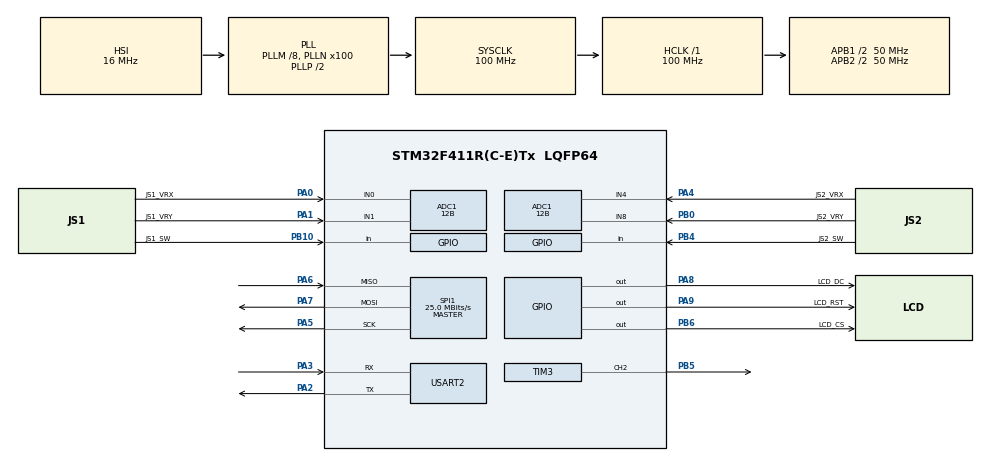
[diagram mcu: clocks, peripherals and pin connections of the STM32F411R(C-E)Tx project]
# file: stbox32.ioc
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ADC1.Channel-0\#ChannelRegularConversion=ADC_CHANNEL_0
ADC1.Channel-6\#ChannelRegularConversion=ADC_CHANNEL_1
ADC1.Channel-7\#ChannelRegularConversion=ADC_CHANNEL_4
ADC1.Channel-8\#ChannelRegularConversion=ADC_CHANNEL_8
ADC1.ContinuousConvMode=ENABLE
ADC1.EOCSelection=ADC_EOC_SINGLE_CONV
ADC1.NbrOfConversion=4
ADC1.NbrOfConversionFlag=1
ADC1.Rank-0\#ChannelRegularConversion=1
ADC1.Rank-6\#ChannelRegularConversion=2
ADC1.Rank-7\#ChannelRegularConversion=3
ADC1.Rank-8\#ChannelRegularConversion=4
ADC1.Resolution=ADC_RESOLUTION_12B
ADC1.SamplingTime-0\#ChannelRegularConversion=ADC_SAMPLETIME_15CYCLES
ADC1.SamplingTime-6\#ChannelRegularConversion=ADC_SAMPLETIME_15CYCLES
ADC1.SamplingTime-7\#ChannelRegularConversion=ADC_SAMPLETIME_15CYCLES
ADC1.SamplingTime-8\#ChannelRegularConversion=ADC_SAMPLETIME_15CYCLES
ADC1.ScanConvMode=ENABLE
ADC1.master=1
Dma.ADC1.0.Direction=DMA_PERIPH_TO_MEMORY
Dma.ADC1.0.FIFOMode=DMA_FIFOMODE_DISABLE
Dma.ADC1.0.Instance=DMA2_Stream0
Dma.ADC1.0.MemDataAlignment=DMA_MDATAALIGN_WORD
Dma.ADC1.0.MemInc=DMA_MINC_ENABLE
Dma.ADC1.0.Mode=DMA_CIRCULAR
Dma.ADC1.0.PeriphDataAlignment=DMA_PDATAALIGN_WORD
Dma.ADC1.0.PeriphInc=DMA_PINC_DISABLE
Dma.ADC1.0.Priority=DMA_PRIORITY_LOW
Dma.Request0=ADC1
Mcu.Family=STM32F4
Mcu.Name=STM32F411R(C-E)Tx
Mcu.Package=LQFP64
NVIC.ADC_IRQn=true\:0\:0\:false\:false\:true\:true\:true\:true
NVIC.DMA2_Stream0_IRQn=true\:0\:0\:false\:false\:true\:false\:true\:true
NVIC.PriorityGroup=NVIC_PRIORITYGROUP_0
NVIC.SPI1_IRQn=true\:0\:0\:false\:false\:true\:true\:true\:true
NVIC.USART2_IRQn=true\:0\:0\:false\:false\:true\:true\:true\:true
PA0-WKUP.GPIO_Label=JS1_VRX
PA0-WKUP.Signal=ADCx_IN0
PA1.GPIO_Label=JS1_VRY
PA1.Signal=ADCx_IN1
PA2.Mode=Asynchronous
PA2.Signal=USART2_TX
PA3.GPIO_PuPd=GPIO_NOPULL
PA3.Mode=Asynchronous
PA3.Signal=USART2_RX
PA4.GPIO_Label=JS2_VRX
PA4.Signal=ADCx_IN4
PA5.Mode=Full_Duplex_Master
PA5.Signal=SPI1_SCK
PA6.GPIO_PuPd=GPIO_NOPULL
PA6.Mode=Full_Duplex_Master
PA6.Signal=SPI1_MISO
PA7.Mode=Full_Duplex_Master
PA7.Signal=SPI1_MOSI
PA8.GPIO_Label=LCD_DC
PA8.GPIO_PuPd=GPIO_NOPULL
PA8.GPIO_Speed=GPIO_SPEED_FREQ_MEDIUM
PA8.PinState=GPIO_PIN_SET
PA8.Signal=GPIO_Output
PA9.GPIO_Label=LCD_RST
PA9.GPIO_PuPd=GPIO_NOPULL
PA9.GPIO_Speed=GPIO_SPEED_FREQ_VERY_HIGH
PA9.PinState=GPIO_PIN_SET
PA9.Signal=GPIO_Output
PB0.GPIO_Label=JS2_VRY
PB0.Signal=ADCx_IN8
PB10.GPIO_Label=JS1_SW
PB10.GPIO_PuPd=GPIO_PULLUP
PB10.Signal=GPIO_Input
PB4.GPIO_Label=JS2_SW
PB4.GPIO_PuPd=GPIO_PULLUP
PB4.Signal=GPIO_Input
PB5.Signal=S_TIM3_CH2
PB6.GPIO_Label=LCD_CS
PB6.GPIO_PuPd=GPIO_NOPULL
PB6.GPIO_Speed=GPIO_SPEED_FREQ_MEDIUM
PB6.PinState=GPIO_PIN_SET
PB6.Signal=GPIO_Output
PH0\ -\ OSC_IN.Mode=HSE-External-Oscillator
PH0\ -\ OSC_IN.Signal=RCC_OSC_IN
PH1\ -\ OSC_OUT.Mode=HSE-External-Oscillator
PH1\ -\ OSC_OUT.Signal=RCC_OSC_OUT
ProjectManager.HeapSize=0x200
ProjectManager.StackSize=0x400
ProjectManager.TargetToolchain=STM32CubeIDE
RCC.48MHZClocksFreq_Value=50000000
RCC.AHBFreq_Value=100000000
RCC.APB1CLKDivider=RCC_HCLK_DIV2
RCC.APB1Freq_Value=50000000
RCC.APB1TimFreq_Value=100000000
RCC.APB2CLKDivider=RCC_HCLK_DIV2
RCC.APB2Freq_Value=50000000
RCC.APB2TimFreq_Value=100000000
RCC.CortexFreq_Value=100000000
RCC.FLatency-AdvancedSettings=FLASH_LATENCY_3
RCC.HCLKFreq_Value=100000000
RCC.HSE_VALUE=8000000
RCC.HSI_VALUE=16000000
RCC.LSE_VALUE=32768
RCC.PLLM=8
RCC.PLLN=100
RCC.SYSCLKFreq_VALUE=100000000
RCC.SYSCLKSource=RCC_SYSCLKSOURCE_PLLCLK
RCC.VCOOutputFreq_Value=200000000
RTC.Hours=3
RTC.Minutes=30
RTC.Seconds=30
SH.ADCx_IN0.0=ADC1_IN0,IN0
SH.ADCx_IN1.0=ADC1_IN1,IN1
SH.ADCx_IN4.0=ADC1_IN4,IN4
SH.ADCx_IN8.0=ADC1_IN8,IN8
SH.S_TIM3_CH2.0=TIM3_CH2,PWM Generation2 CH2
SPI1.CalculateBaudRate=25.0 MBits/s
SPI1.Direction=SPI_DIRECTION_2LINES
SPI1.Mode=SPI_MODE_MASTER
SPI1.VirtualType=VM_MASTER
TIM3.Channel-PWM\ Generation2\ CH2=TIM_CHANNEL_2
TIM3.Period=999
TIM3.Prescaler=83
USART2.VirtualMode=VM_ASYNC
VP_RTC_VS_RTC_Activate.Mode=RTC_Enabled
VP_RTC_VS_RTC_Calendar.Mode=RTC_Calendar
VP_TIM3_VS_ClockSourceINT.Mode=Internal
board=NUCLEO-F411RE

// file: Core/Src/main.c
/* USER CODE BEGIN Header */
/**
  ******************************************************************************
  * @file           : main.c
  * @brief          : Main program body
  ******************************************************************************
  * @attention
  *
  * Copyright (c) 2025 STMicroelectronics.
  * All rights reserved.
  *
  * This software is licensed under terms that can be found in the LICENSE file
  * in the root directory of this software component.
  * If no LICENSE file comes with this software, it is provided AS-IS.
  *
  ******************************************************************************
  */
/* USER CODE END Header */
#include "main.h"

/* USER CODE BEGIN Includes */
#include "main_menu.h"
/* USER CODE END Includes */

ADC_HandleTypeDef hadc1;
DMA_HandleTypeDef hdma_adc1;

RTC_HandleTypeDef hrtc;

SPI_HandleTypeDef hspi1;

TIM_HandleTypeDef htim3;

UART_HandleTypeDef huart2;

void SystemClock_Config(void);
static void MX_GPIO_Init(void);
static void MX_DMA_Init(void);
static void MX_RTC_Init(void);
static void MX_SPI1_Init(void);
static void MX_USART2_UART_Init(void);
static void MX_ADC1_Init(void);
static void MX_TIM3_Init(void);

int main(void)
{

  /* MCU Configuration--------------------------------------------------------*/

  /* Reset of all peripherals, Initializes the Flash interface and the Systick. */
  HAL_Init();

  /* Configure the system clock */
  SystemClock_Config();

  /* Initialize all configured peripherals */
  MX_GPIO_Init();
  MX_DMA_Init();
  MX_RTC_Init();
  MX_SPI1_Init();
  MX_USART2_UART_Init();  MX_ADC1_Init();
  MX_TIM3_Init();
  /* USER CODE BEGIN 2 */
  HAL_TIM_PWM_Start(&htim3, TIM_CHANNEL_2);
  Joystick_Init();  // Initialize joysticks after ADC
  lcd_init();
  srand(HAL_GetTick());
  HAL_ADC_Start(&hadc1);

  lcd_clear_screen(BLACK);  /* USER CODE END 2 */  /* Infinite loop */
  /* USER CODE BEGIN WHILE */

  // Start the main menu system
  main_menu_run();

  while (1)
  {
    /* USER CODE END WHILE */

  }
}

void SystemClock_Config(void)
{
  RCC_OscInitTypeDef RCC_OscInitStruct = {0};
  RCC_ClkInitTypeDef RCC_ClkInitStruct = {0};

  /** Configure the main internal regulator output voltage
  */
  __HAL_RCC_PWR_CLK_ENABLE();
  __HAL_PWR_VOLTAGESCALING_CONFIG(PWR_REGULATOR_VOLTAGE_SCALE1);

  /** Initializes the RCC Oscillators according to the specified parameters
  * in the RCC_OscInitTypeDef structure.
  */
  RCC_OscInitStruct.OscillatorType = RCC_OSCILLATORTYPE_HSI|RCC_OSCILLATORTYPE_LSI;
  RCC_OscInitStruct.HSIState = RCC_HSI_ON;
  RCC_OscInitStruct.HSICalibrationValue = RCC_HSICALIBRATION_DEFAULT;
  RCC_OscInitStruct.LSIState = RCC_LSI_ON;
  RCC_OscInitStruct.PLL.PLLState = RCC_PLL_ON;
  RCC_OscInitStruct.PLL.PLLSource = RCC_PLLSOURCE_HSI;
  RCC_OscInitStruct.PLL.PLLM = 8;
  RCC_OscInitStruct.PLL.PLLN = 100;
  RCC_OscInitStruct.PLL.PLLP = RCC_PLLP_DIV2;
  RCC_OscInitStruct.PLL.PLLQ = 4;
  if (HAL_RCC_OscConfig(&RCC_OscInitStruct) != HAL_OK)
  {
    Error_Handler();
  }

  /** Initializes the CPU, AHB and APB buses clocks
  */
  RCC_ClkInitStruct.ClockType = RCC_CLOCKTYPE_HCLK|RCC_CLOCKTYPE_SYSCLK
                              |RCC_CLOCKTYPE_PCLK1|RCC_CLOCKTYPE_PCLK2;
  RCC_ClkInitStruct.SYSCLKSource = RCC_SYSCLKSOURCE_PLLCLK;
  RCC_ClkInitStruct.AHBCLKDivider = RCC_SYSCLK_DIV1;
  RCC_ClkInitStruct.APB1CLKDivider = RCC_HCLK_DIV2;
  RCC_ClkInitStruct.APB2CLKDivider = RCC_HCLK_DIV2;

  if (HAL_RCC_ClockConfig(&RCC_ClkInitStruct, FLASH_LATENCY_3) != HAL_OK)
  {
    Error_Handler();
  }
}

static void MX_ADC1_Init(void)
{

  ADC_ChannelConfTypeDef sConfig = {0};

  /** Configure the global features of the ADC (Clock, Resolution, Data Alignment and number of conversion)
  */
  hadc1.Instance = ADC1;
  hadc1.Init.ClockPrescaler = ADC_CLOCK_SYNC_PCLK_DIV2;
  hadc1.Init.Resolution = ADC_RESOLUTION_12B;
  hadc1.Init.ScanConvMode = ENABLE;
  hadc1.Init.ContinuousConvMode = ENABLE;
  hadc1.Init.DiscontinuousConvMode = DISABLE;
  hadc1.Init.ExternalTrigConvEdge = ADC_EXTERNALTRIGCONVEDGE_NONE;
  hadc1.Init.ExternalTrigConv = ADC_SOFTWARE_START;  hadc1.Init.DataAlign = ADC_DATAALIGN_RIGHT;
  hadc1.Init.NbrOfConversion = 4;  // Changed from 2 to 4 channels
  hadc1.Init.DMAContinuousRequests = DISABLE;
  hadc1.Init.EOCSelection = ADC_EOC_SINGLE_CONV;
  if (HAL_ADC_Init(&hadc1) != HAL_OK)
  {
    Error_Handler();
  }

  /** Configure for the selected ADC regular channel its corresponding rank in the sequencer and its sample time.
  */
  sConfig.Channel = ADC_CHANNEL_0;
  sConfig.Rank = 1;
  sConfig.SamplingTime = ADC_SAMPLETIME_15CYCLES;
  if (HAL_ADC_ConfigChannel(&hadc1, &sConfig) != HAL_OK)
  {
    Error_Handler();
  }
  /** Configure for the selected ADC regular channel its corresponding rank in the sequencer and its sample time.
  */
  sConfig.Channel = ADC_CHANNEL_1;
  sConfig.Rank = 2;
  if (HAL_ADC_ConfigChannel(&hadc1, &sConfig) != HAL_OK)
  {
    Error_Handler();
  }

  /** Configure for the selected ADC regular channel its corresponding rank in the sequencer and its sample time.
  */
  sConfig.Channel = ADC_CHANNEL_4;
  sConfig.Rank = 3;
  sConfig.SamplingTime = ADC_SAMPLETIME_15CYCLES;
  if (HAL_ADC_ConfigChannel(&hadc1, &sConfig) != HAL_OK)
  {
    Error_Handler();
  }

  /** Configure for the selected ADC regular channel its corresponding rank in the sequencer and its sample time.
  */
  sConfig.Channel = ADC_CHANNEL_8;
  sConfig.Rank = 4;
  sConfig.SamplingTime = ADC_SAMPLETIME_15CYCLES;
  if (HAL_ADC_ConfigChannel(&hadc1, &sConfig) != HAL_OK)
  {
    Error_Handler();
  }

}

static void MX_RTC_Init(void)
{

  RTC_TimeTypeDef sTime = {0};
  RTC_DateTypeDef sDate = {0};

  /** Initialize RTC Only
  */
  hrtc.Instance = RTC;
  hrtc.Init.HourFormat = RTC_HOURFORMAT_24;
  hrtc.Init.AsynchPrediv = 127;
  hrtc.Init.SynchPrediv = 255;
  hrtc.Init.OutPut = RTC_OUTPUT_DISABLE;
  hrtc.Init.OutPutPolarity = RTC_OUTPUT_POLARITY_HIGH;
  hrtc.Init.OutPutType = RTC_OUTPUT_TYPE_OPENDRAIN;
  if (HAL_RTC_Init(&hrtc) != HAL_OK)
  {
    Error_Handler();
  }

  /** Initialize RTC and set the Time and Date
  */
  sTime.Hours = 0x3;
  sTime.Minutes = 0x30;
  sTime.Seconds = 0x30;
  sTime.DayLightSaving = RTC_DAYLIGHTSAVING_NONE;
  sTime.StoreOperation = RTC_STOREOPERATION_RESET;
  if (HAL_RTC_SetTime(&hrtc, &sTime, RTC_FORMAT_BCD) != HAL_OK)
  {
    Error_Handler();
  }
  sDate.WeekDay = RTC_WEEKDAY_MONDAY;
  sDate.Month = RTC_MONTH_JANUARY;
  sDate.Date = 0x1;
  sDate.Year = 0x0;

  if (HAL_RTC_SetDate(&hrtc, &sDate, RTC_FORMAT_BCD) != HAL_OK)
  {
    Error_Handler();
  }

}

static void MX_SPI1_Init(void)
{

  /* SPI1 parameter configuration*/
  hspi1.Instance = SPI1;
  hspi1.Init.Mode = SPI_MODE_MASTER;
  hspi1.Init.Direction = SPI_DIRECTION_2LINES;
  hspi1.Init.DataSize = SPI_DATASIZE_8BIT;
  hspi1.Init.CLKPolarity = SPI_POLARITY_LOW;
  hspi1.Init.CLKPhase = SPI_PHASE_1EDGE;
  hspi1.Init.NSS = SPI_NSS_SOFT;
  hspi1.Init.BaudRatePrescaler = SPI_BAUDRATEPRESCALER_2;
  hspi1.Init.FirstBit = SPI_FIRSTBIT_MSB;
  hspi1.Init.TIMode = SPI_TIMODE_DISABLE;
  hspi1.Init.CRCCalculation = SPI_CRCCALCULATION_DISABLE;
  hspi1.Init.CRCPolynomial = 10;
  if (HAL_SPI_Init(&hspi1) != HAL_OK)
  {
    Error_Handler();
  }

}

static void MX_TIM3_Init(void)
{

  TIM_ClockConfigTypeDef sClockSourceConfig = {0};
  TIM_MasterConfigTypeDef sMasterConfig = {0};
  TIM_OC_InitTypeDef sConfigOC = {0};

  htim3.Instance = TIM3;
  htim3.Init.Prescaler = 83;
  htim3.Init.CounterMode = TIM_COUNTERMODE_UP;
  htim3.Init.Period = 999;
  htim3.Init.ClockDivision = TIM_CLOCKDIVISION_DIV1;
  htim3.Init.AutoReloadPreload = TIM_AUTORELOAD_PRELOAD_DISABLE;
  if (HAL_TIM_Base_Init(&htim3) != HAL_OK)
  {
    Error_Handler();
  }
  sClockSourceConfig.ClockSource = TIM_CLOCKSOURCE_INTERNAL;
  if (HAL_TIM_ConfigClockSource(&htim3, &sClockSourceConfig) != HAL_OK)
  {
    Error_Handler();
  }
  if (HAL_TIM_PWM_Init(&htim3) != HAL_OK)
  {
    Error_Handler();
  }
  sMasterConfig.MasterOutputTrigger = TIM_TRGO_RESET;
  sMasterConfig.MasterSlaveMode = TIM_MASTERSLAVEMODE_DISABLE;
  if (HAL_TIMEx_MasterConfigSynchronization(&htim3, &sMasterConfig) != HAL_OK)
  {
    Error_Handler();
  }
  sConfigOC.OCMode = TIM_OCMODE_PWM1;
  sConfigOC.Pulse = 0;
  sConfigOC.OCPolarity = TIM_OCPOLARITY_HIGH;
  sConfigOC.OCFastMode = TIM_OCFAST_DISABLE;
  if (HAL_TIM_PWM_ConfigChannel(&htim3, &sConfigOC, TIM_CHANNEL_2) != HAL_OK)
  {
    Error_Handler();
  }
  HAL_TIM_MspPostInit(&htim3);

}

static void MX_USART2_UART_Init(void)
{

  huart2.Instance = USART2;
  huart2.Init.BaudRate = 115200;
  huart2.Init.WordLength = UART_WORDLENGTH_8B;
  huart2.Init.StopBits = UART_STOPBITS_1;
  huart2.Init.Parity = UART_PARITY_NONE;
  huart2.Init.Mode = UART_MODE_TX_RX;
  huart2.Init.HwFlowCtl = UART_HWCONTROL_NONE;
  huart2.Init.OverSampling = UART_OVERSAMPLING_16;
  if (HAL_UART_Init(&huart2) != HAL_OK)
  {
    Error_Handler();
  }

}

static void MX_DMA_Init(void)
{

  /* DMA controller clock enable */
  __HAL_RCC_DMA2_CLK_ENABLE();

  /* DMA interrupt init */
  /* DMA2_Stream0_IRQn interrupt configuration */
  HAL_NVIC_SetPriority(DMA2_Stream0_IRQn, 0, 0);
  HAL_NVIC_EnableIRQ(DMA2_Stream0_IRQn);

}

static void MX_GPIO_Init(void)
{
  GPIO_InitTypeDef GPIO_InitStruct = {0};

  /* GPIO Ports Clock Enable */
  __HAL_RCC_GPIOH_CLK_ENABLE();
  __HAL_RCC_GPIOA_CLK_ENABLE();
  __HAL_RCC_GPIOB_CLK_ENABLE();

  /*Configure GPIO pin Output Level */
  HAL_GPIO_WritePin(GPIOA, LCD_DC_Pin|LCD_RST_Pin, GPIO_PIN_SET);

  /*Configure GPIO pin Output Level */
  HAL_GPIO_WritePin(LCD_CS_GPIO_Port, LCD_CS_Pin, GPIO_PIN_SET);

  /*Configure GPIO pins : JS1_SW_Pin JS2_SW_Pin */
  GPIO_InitStruct.Pin = JS1_SW_Pin|JS2_SW_Pin;
  GPIO_InitStruct.Mode = GPIO_MODE_INPUT;
  GPIO_InitStruct.Pull = GPIO_PULLUP;
  HAL_GPIO_Init(GPIOB, &GPIO_InitStruct);

  /*Configure GPIO pin : LCD_DC_Pin */
  GPIO_InitStruct.Pin = LCD_DC_Pin;
  GPIO_InitStruct.Mode = GPIO_MODE_OUTPUT_PP;
  GPIO_InitStruct.Pull = GPIO_NOPULL;
  GPIO_InitStruct.Speed = GPIO_SPEED_FREQ_MEDIUM;
  HAL_GPIO_Init(LCD_DC_GPIO_Port, &GPIO_InitStruct);

  /*Configure GPIO pin : LCD_RST_Pin */
  GPIO_InitStruct.Pin = LCD_RST_Pin;
  GPIO_InitStruct.Mode = GPIO_MODE_OUTPUT_PP;
  GPIO_InitStruct.Pull = GPIO_NOPULL;
  GPIO_InitStruct.Speed = GPIO_SPEED_FREQ_VERY_HIGH;
  HAL_GPIO_Init(LCD_RST_GPIO_Port, &GPIO_InitStruct);

  /*Configure GPIO pin : LCD_CS_Pin */
  GPIO_InitStruct.Pin = LCD_CS_Pin;
  GPIO_InitStruct.Mode = GPIO_MODE_OUTPUT_PP;
  GPIO_InitStruct.Pull = GPIO_NOPULL;
  GPIO_InitStruct.Speed = GPIO_SPEED_FREQ_MEDIUM;
  HAL_GPIO_Init(LCD_CS_GPIO_Port, &GPIO_InitStruct);

}

void Error_Handler(void)
{
  __disable_irq();
  while (1)
  {
  }
}
